VERSION ""

NS_ :

BS_:

BU_: MASTER MOTOR SENSOR COM_BRIDGE GPS

BO_ 162 GPS_CURRENT_LOCATION: 8 GPS
 SG_ GPS_LATTITUDE_SIGNED : 0|30@1+ (0.000001,-90) [-90|90] "degrees" COM_BRIDGE
 SG_ GPS_LONGITUDE_SIGNED : 30|30@1+ (0.000001,-180) [-180|180] "degrees" COM_BRIDGE

BO_ 148 COM_BRIDGE_CHECK_POINT: 8 COM_BRIDGE
 SG_ COM_BRIDGE_MUX M : 0|2@1+ (1,0) [0|0] "" GPS
 SG_ COM_BRIDGE_COUNT_UNSIGNED : 2|8@1+ (1,0) [0|0] "count" GPS
 SG_ COM_BRIDGE_LATTITUDE_SIGNED m0 : 10|40@1+ (0.000001,-90) [-90|90] "degrees" GPS
 SG_ COM_BRIDGE_LONGITUDE_SIGNED m1 : 10|40@1+ (0.000001,-180) [-180|180] "degrees" GPS

BO_ 2 MASTER_INITIATE_STEP_SECOND: 2 MASTER
 SG_ MASTER_INITIATE_UNSIGNED : 0|8@1+ (1,0) [0|0] "" MOTOR,SENSOR

BO_ 84 COM_BRIDGE_CLICKED_START: 2 COM_BRIDGE
 SG_ COM_BRIDGE_CLICKED_START_UNSIGNED : 0|8@1+ (1,0) [0|0] "" MASTER,GPS

BO_ 26 MASTER_INITIATE_STEP_FIRST: 2 MASTER
 SG_ MASTER_INITIATE_UNSIGNED : 0|8@1+ (1,0) [0|0] "" COM_BRIDGE,GPS

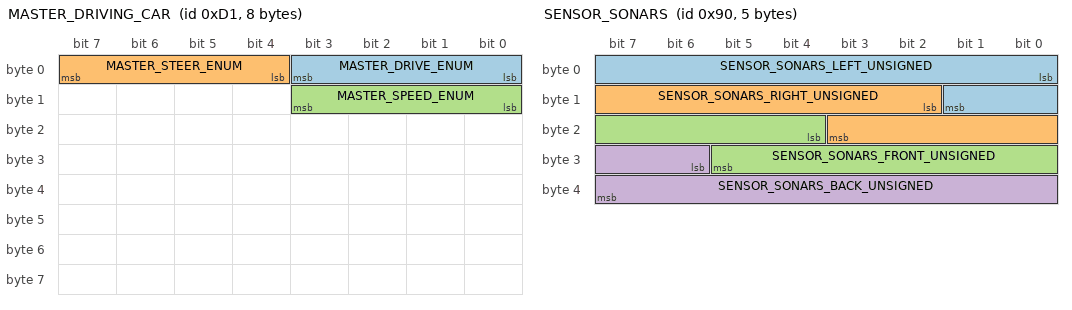
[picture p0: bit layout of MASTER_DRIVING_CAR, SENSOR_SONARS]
BO_ 209 MASTER_DRIVING_CAR: 8 MASTER
 SG_ MASTER_DRIVE_ENUM : 0|4@1+ (1,0) [0|0] "" MOTOR
 SG_ MASTER_STEER_ENUM : 4|4@1+ (1,0) [0|0] "" MOTOR
 SG_ MASTER_SPEED_ENUM : 8|4@1+ (1,0) [0|0] "" MOTOR

BO_ 144 SENSOR_SONARS: 5 SENSOR
 SG_ SENSOR_SONARS_LEFT_UNSIGNED : 0|10@1+ (1,0) [0|0] "inches" MASTER
 SG_ SENSOR_SONARS_RIGHT_UNSIGNED : 10|10@1+ (1,0) [0|0] "inches" MASTER
 SG_ SENSOR_SONARS_FRONT_UNSIGNED : 20|10@1+ (1,0) [0|0] "inches" MASTER
 SG_ SENSOR_SONARS_BACK_UNSIGNED : 30|10@1+ (1,0) [0|0] "inches" MASTER

BO_ 339 MOTOR_HEARTBEAT: 1 MOTOR
 SG_ MOTOR_HEARTBEAT_UNSIGNED : 0|8@1+ (1,0) [0|0] "" MASTER

BO_ 147 MOTOR_CAR_SPEED: 8 MOTOR
 SG_ MOTOR_SPEED_DATA_UNSIGNED : 0|8@1+ (1,0) [0|0] "" MASTER

BO_ 4 COM_BRIDGE_STOPALL: 1 COM_BRIDGE
 SG_ COM_BRIDGE_STOPALL_UNSIGNED : 0|8@1+ (1,0) [0|0] "" MASTER,GPS,MOTOR,SENSOR

BO_ 336 SENSOR_HEARTBEAT: 1 SENSOR
 SG_ SENSOR_HEARTBEAT_UNSIGNED : 0|8@1+ (1,0) [0|0] "" MASTER

BO_ 338 GPS_HEARTBEAT: 1 GPS
 SG_ GPS_HEARTBEAT_UNSIGNED : 0|8@1+ (1,0) [0|0] "" MASTER

BO_ 340 COM_BRIDGE_HEARTBEAT: 1 COM_BRIDGE
 SG_ COM_BRIDGE_HEARTBEAT_UNSIGNED : 0|8@1+ (1,0) [0|0] "" MASTER

BO_ 281 MASTER_ACKNOWLEDGEMENT: 1 MASTER
 SG_ ACKNOWLEDGEMENT_DATA_REACHED_UNSIGNED : 0|8@1+ (1,0) [0|0] "" GPS

BO_ 290 GPS_ACKNOWLEDGEMENT: 1 GPS
 SG_ GPS_ACKNOWLEDGEMENT_UNSIGNED : 0|8@1+ (1,0) [0|0] "" COM_BRIDGE

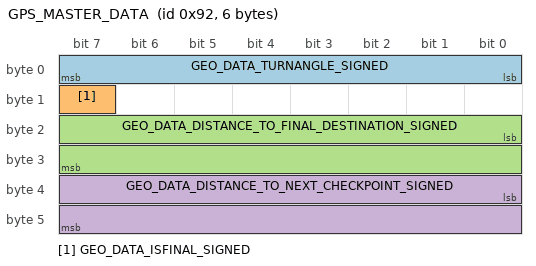
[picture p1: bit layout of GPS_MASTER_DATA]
BO_ 146 GPS_MASTER_DATA: 6 GPS
 SG_ GEO_DATA_TURNANGLE_SIGNED : 0|8@1+ (1,0) [0|0] "" MASTER
 SG_ GEO_DATA_ISFINAL_SIGNED : 15|1@1+ (1,0) [0|0] "" MASTER
 SG_ GEO_DATA_DISTANCE_TO_FINAL_DESTINATION_SIGNED : 16|16@1+ (1,0) [0|0] "" MASTER
 SG_ GEO_DATA_DISTANCE_TO_NEXT_CHECKPOINT_SIGNED : 32|16@1+ (1,0) [0|0] "" MASTER

BA_ "FieldType" SG_ 209 MASTER_DRIVE_ENUM "MASTER_DRIVE_ENUM";
BA_ "FieldType" SG_ 209 MASTER_STEER_ENUM "MASTER_STEER_ENUM";
BA_ "FieldType" SG_ 209 MASTER_SPEED_ENUM "MASTER_SPEED_ENUM";

VAL_ 209 MASTER_DRIVE_ENUM 3 "DRIVE" 2 "STOP" 1 "REVERSE" ;
VAL_ 209 MASTER_STEER_ENUM 5 "FAR_LEFT" 4 "LEFT" 3 "CENTER" 2 "RIGHT" 1 "FAR_RIGHT" ;
VAL_ 209 MASTER_SPEED_ENUM 3 "HIGH" 2 "MEDIUM" 1 "LOW"

BA_DEF_ "BusType" STRING ;
BA_DEF_ SG_ "FieldType" STRING ;

BA_DEF_DEF_ "BusType" "CAN";
BA_DEF_DEF_ "FieldType" "";
